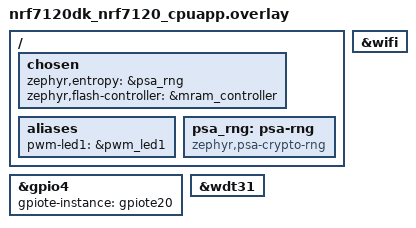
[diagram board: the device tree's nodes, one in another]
/*
 * Copyright (c) 2026 Nordic Semiconductor ASA
 *
 * SPDX-License-Identifier: LicenseRef-Nordic-5-Clause
 */

#include <nrf7120_cpuapp_partitions.dtsi>

/ {
	chosen {
		zephyr,entropy = &psa_rng;
		// TODO: MRAM is not chosen as the flash controller by default
		zephyr,flash-controller = &mram_controller;
	};

	aliases {
		pwm-led1 = &pwm_led1;
	};

	psa_rng: psa-rng {
		compatible = "zephyr,psa-crypto-rng";
		status = "okay";
	};
};

// TODO: gpio4 has no gpiote instance assigned in the dtsi file
&gpio4 {
	gpiote-instance = <&gpiote20>;
};

&wdt31 {
	status = "okay";
};

&wifi {
	status = "okay";
};
